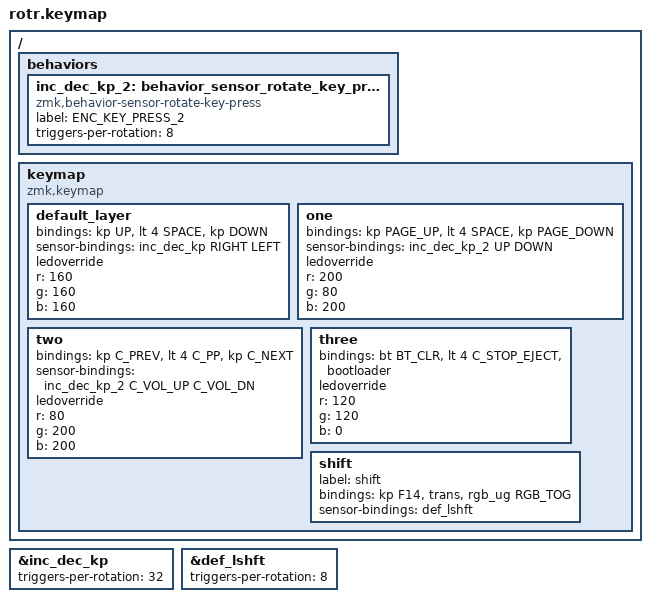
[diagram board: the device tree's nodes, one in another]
#include <behaviors.dtsi>
#include <dt-bindings/zmk/keys.h>
#include <dt-bindings/zmk/rgb.h>
#include <dt-bindings/zmk/bt.h>

/ {
	behaviors {
		inc_dec_kp_2: behavior_sensor_rotate_key_press_2 {
			compatible = "zmk,behavior-sensor-rotate-key-press";
			label = "ENC_KEY_PRESS_2";
			triggers-per-rotation = <8>;
			#sensor-binding-cells = <2>;
			
		};
	};
};

&inc_dec_kp {
	triggers-per-rotation = <32>;
};
&def_lshft {
	triggers-per-rotation = <8>;
};

/ {
	keymap {
		compatible = "zmk,keymap";

		default_layer {
			//LCTRL | space | LALT   RGB 160 160 160 
			bindings = <&kp UP &lt 4 SPACE &kp DOWN>;
			sensor-bindings = <&inc_dec_kp RIGHT LEFT>;
			ledoverride;
            		r = <160>;
           		g = <160>;
           		b = <160>;
		};
		one {
			//Left | Space | Right   RGB 200 80 200
			bindings = <&kp PAGE_UP &lt 4 SPACE &kp PAGE_DOWN>;
			sensor-bindings = <&inc_dec_kp_2 UP DOWN>;
			ledoverride;
            		r = <200>;
           		g = <80>;
           		b = <200>;
		};
		two {		
			//Previous Track | Player/pause | Next Track  RGB 80 200 200
			bindings = <&kp C_PREV &lt 4 C_PP &kp C_NEXT>;
			sensor-bindings = <&inc_dec_kp_2 C_VOL_UP C_VOL_DN>;
			ledoverride;
            		r = <80>;
           		g = <200>;
           		b = <200>;
		};
		three {
			//BT clear | RGB toggle | Flash   RGB 250 0 0
			bindings = <&bt BT_CLR &lt 4 C_STOP_EJECT &bootloader>;
//			sensor-bindings = <&inc_dec_kp_2 PG_UP PG_DN>;
			ledoverride;
            		r = <120>;
           		g = <120>;
           		b = <0>;
		};
		shift {
			label = "shift";
			//F14| Trans | page down
			bindings = <&kp F14 &trans &rgb_ug RGB_TOG>;
			sensor-bindings = <&def_lshft>;
		};
	};
};
